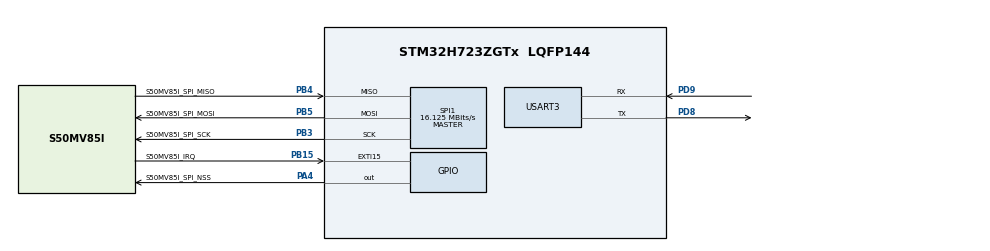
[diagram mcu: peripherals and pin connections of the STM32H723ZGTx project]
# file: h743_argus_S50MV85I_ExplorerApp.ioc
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CORTEX_M7.default_mode_Activation=1
Dma.Request0=SPI1_RX
Dma.Request1=SPI1_TX
Dma.Request2=USART3_RX
Dma.Request3=USART3_TX
Dma.SPI1_RX.0.Direction=DMA_PERIPH_TO_MEMORY
Dma.SPI1_RX.0.EventEnable=DISABLE
Dma.SPI1_RX.0.FIFOMode=DMA_FIFOMODE_DISABLE
Dma.SPI1_RX.0.Instance=DMA1_Stream0
Dma.SPI1_RX.0.MemDataAlignment=DMA_MDATAALIGN_BYTE
Dma.SPI1_RX.0.MemInc=DMA_MINC_ENABLE
Dma.SPI1_RX.0.Mode=DMA_NORMAL
Dma.SPI1_RX.0.PeriphDataAlignment=DMA_PDATAALIGN_BYTE
Dma.SPI1_RX.0.PeriphInc=DMA_PINC_DISABLE
Dma.SPI1_RX.0.Polarity=HAL_DMAMUX_REQ_GEN_RISING
Dma.SPI1_RX.0.Priority=DMA_PRIORITY_LOW
Dma.SPI1_RX.0.RequestNumber=1
Dma.SPI1_RX.0.SignalID=NONE
Dma.SPI1_RX.0.SyncEnable=DISABLE
Dma.SPI1_RX.0.SyncPolarity=HAL_DMAMUX_SYNC_NO_EVENT
Dma.SPI1_RX.0.SyncRequestNumber=1
Dma.SPI1_RX.0.SyncSignalID=NONE
Dma.SPI1_TX.1.Direction=DMA_MEMORY_TO_PERIPH
Dma.SPI1_TX.1.EventEnable=DISABLE
Dma.SPI1_TX.1.FIFOMode=DMA_FIFOMODE_DISABLE
Dma.SPI1_TX.1.Instance=DMA1_Stream1
Dma.SPI1_TX.1.MemDataAlignment=DMA_MDATAALIGN_BYTE
Dma.SPI1_TX.1.MemInc=DMA_MINC_ENABLE
Dma.SPI1_TX.1.Mode=DMA_NORMAL
Dma.SPI1_TX.1.PeriphDataAlignment=DMA_PDATAALIGN_BYTE
Dma.SPI1_TX.1.PeriphInc=DMA_PINC_DISABLE
Dma.SPI1_TX.1.Polarity=HAL_DMAMUX_REQ_GEN_RISING
Dma.SPI1_TX.1.Priority=DMA_PRIORITY_LOW
Dma.SPI1_TX.1.RequestNumber=1
Dma.SPI1_TX.1.SignalID=NONE
Dma.SPI1_TX.1.SyncEnable=DISABLE
Dma.SPI1_TX.1.SyncPolarity=HAL_DMAMUX_SYNC_NO_EVENT
Dma.SPI1_TX.1.SyncRequestNumber=1
Dma.SPI1_TX.1.SyncSignalID=NONE
Dma.USART3_RX.2.Direction=DMA_PERIPH_TO_MEMORY
Dma.USART3_RX.2.EventEnable=DISABLE
Dma.USART3_RX.2.FIFOMode=DMA_FIFOMODE_DISABLE
Dma.USART3_RX.2.Instance=DMA1_Stream2
Dma.USART3_RX.2.MemDataAlignment=DMA_MDATAALIGN_BYTE
Dma.USART3_RX.2.MemInc=DMA_MINC_ENABLE
Dma.USART3_RX.2.Mode=DMA_NORMAL
Dma.USART3_RX.2.PeriphDataAlignment=DMA_PDATAALIGN_BYTE
Dma.USART3_RX.2.PeriphInc=DMA_PINC_DISABLE
Dma.USART3_RX.2.Polarity=HAL_DMAMUX_REQ_GEN_RISING
Dma.USART3_RX.2.Priority=DMA_PRIORITY_LOW
Dma.USART3_RX.2.RequestNumber=1
Dma.USART3_RX.2.SignalID=NONE
Dma.USART3_RX.2.SyncEnable=DISABLE
Dma.USART3_RX.2.SyncPolarity=HAL_DMAMUX_SYNC_NO_EVENT
Dma.USART3_RX.2.SyncRequestNumber=1
Dma.USART3_RX.2.SyncSignalID=NONE
Dma.USART3_TX.3.Direction=DMA_MEMORY_TO_PERIPH
Dma.USART3_TX.3.EventEnable=DISABLE
Dma.USART3_TX.3.FIFOMode=DMA_FIFOMODE_DISABLE
Dma.USART3_TX.3.Instance=DMA1_Stream3
Dma.USART3_TX.3.MemDataAlignment=DMA_MDATAALIGN_BYTE
Dma.USART3_TX.3.MemInc=DMA_MINC_ENABLE
Dma.USART3_TX.3.Mode=DMA_NORMAL
Dma.USART3_TX.3.PeriphDataAlignment=DMA_PDATAALIGN_BYTE
Dma.USART3_TX.3.PeriphInc=DMA_PINC_DISABLE
Dma.USART3_TX.3.Polarity=HAL_DMAMUX_REQ_GEN_RISING
Dma.USART3_TX.3.Priority=DMA_PRIORITY_LOW
Dma.USART3_TX.3.RequestNumber=1
Dma.USART3_TX.3.SignalID=NONE
Dma.USART3_TX.3.SyncEnable=DISABLE
Dma.USART3_TX.3.SyncPolarity=HAL_DMAMUX_SYNC_NO_EVENT
Dma.USART3_TX.3.SyncRequestNumber=1
Dma.USART3_TX.3.SyncSignalID=NONE
Mcu.Family=STM32H7
Mcu.Name=STM32H723ZGTx
Mcu.Package=LQFP144
Mcu.UserConstants=TIM5_BUS_CLK,(HAL_RCC_GetPCLK1Freq() << 1);TIM6_BUS_CLK,(HAL_RCC_GetPCLK1Freq() << 1)
NVIC.DMA1_Stream0_IRQn=true\:0\:0\:false\:false\:true\:false\:true\:true
NVIC.DMA1_Stream1_IRQn=true\:0\:0\:false\:false\:true\:false\:true\:true
NVIC.DMA1_Stream2_IRQn=true\:0\:0\:false\:false\:true\:false\:true\:true
NVIC.DMA1_Stream3_IRQn=true\:0\:0\:false\:false\:true\:false\:true\:true
NVIC.EXTI15_10_IRQn=true\:2\:0\:true\:false\:true\:true\:true\:true
NVIC.PriorityGroup=NVIC_PRIORITYGROUP_4
NVIC.SPI1_IRQn=true\:1\:0\:true\:false\:true\:false\:true\:true
NVIC.TIM6_DAC_IRQn=true\:3\:0\:true\:false\:true\:true\:true\:true
NVIC.USART3_IRQn=true\:0\:0\:false\:false\:true\:true\:true\:true
PA4.GPIO_Label=S50MV85I_SPI_NSS
PA4.GPIO_Speed=GPIO_SPEED_FREQ_VERY_HIGH
PA4.PinState=GPIO_PIN_SET
PA4.Signal=GPIO_Output
PB15.GPIO_Label=S50MV85I_IRQ
PB15.GPIO_ModeDefaultEXTI=GPIO_MODE_IT_FALLING
PB15.GPIO_PuPd=GPIO_PULLUP
PB15.Signal=GPXTI15
PB3(JTDO/TRACESWO).GPIO_Label=S50MV85I_SPI_SCK
PB3(JTDO/TRACESWO).Mode=Full_Duplex_Master
PB3(JTDO/TRACESWO).Signal=SPI1_SCK
PB4(NJTRST).GPIO_Label=S50MV85I_SPI_MISO
PB4(NJTRST).Mode=Full_Duplex_Master
PB4(NJTRST).Signal=SPI1_MISO
PB5.GPIO_Label=S50MV85I_SPI_MOSI
PB5.Mode=Full_Duplex_Master
PB5.Signal=SPI1_MOSI
PD8.Mode=Asynchronous
PD8.Signal=USART3_TX
PD9.Mode=Asynchronous
PD9.Signal=USART3_RX
ProjectManager.HeapSize=0x2000
ProjectManager.StackSize=0x5000
ProjectManager.TargetToolchain=STM32CubeIDE
RCC.ADCFreq_Value=129000000
RCC.APB1Freq_Value=137500000
RCC.APB2Freq_Value=137500000
RCC.APB3Freq_Value=137500000
RCC.APB4Freq_Value=137500000
RCC.CortexFreq_Value=550000000
RCC.D1PPRE=RCC_APB3_DIV2
RCC.D2PPRE1=RCC_APB1_DIV2
RCC.D2PPRE2=RCC_APB2_DIV2
RCC.D3PPRE=RCC_APB4_DIV2
RCC.DIVM1=4
RCC.DIVN1=34
RCC.DIVP1=1
RCC.HCLKFreq_Value=275000000
RCC.HPRE=RCC_HCLK_DIV2
RCC.PLLFRACN=3072
RCC.SPI123CLockSelection=RCC_SPI123CLKSOURCE_PLL2
RCC.SYSCLKFreq_VALUE=550000000
RCC.SYSCLKSource=RCC_SYSCLKSOURCE_PLLCLK
RCC.USBFreq_Value=275000000
SPI1.BaudRatePrescaler=SPI_BAUDRATEPRESCALER_8
SPI1.CLKPhase=SPI_PHASE_2EDGE
SPI1.CLKPolarity=SPI_POLARITY_HIGH
SPI1.CalculateBaudRate=16.125 MBits/s
SPI1.DataSize=SPI_DATASIZE_8BIT
SPI1.Direction=SPI_DIRECTION_2LINES
SPI1.MasterKeepIOState=SPI_MASTER_KEEP_IO_STATE_ENABLE
SPI1.Mode=SPI_MODE_MASTER
SPI1.VirtualType=VM_MASTER
TIM5.Prescaler=(TIM5_BUS_CLK / 1000000) - 1
TIM5.TIM_MasterOutputTrigger=TIM_TRGO_UPDATE
TIM6.Prescaler=(TIM6_BUS_CLK / 1000000) - 1
TIM6.TIM_MasterOutputTrigger=TIM_TRGO_ENABLE
USART3.DMADisableonRxErrorParam=ADVFEATURE_DMA_DISABLEONRXERROR
USART3.OverrunDisableParam=ADVFEATURE_OVERRUN_DISABLE
USART3.VirtualMode-Asynchronous=VM_ASYNC
VP_TIM5_VS_ClockSourceINT.Mode=Internal
VP_TIM6_VS_ClockSourceINT.Mode=Enable_Timer
board=custom

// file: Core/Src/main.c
/* USER CODE BEGIN Header */
/**
  ******************************************************************************
  * @file           : main.c
  * @brief          : Main program body
  ******************************************************************************
  * @attention
  *
  * Copyright (c) 2024 STMicroelectronics.
  * All rights reserved.
  *
  * This software is licensed under terms that can be found in the LICENSE file
  * in the root directory of this software component.
  * If no LICENSE file comes with this software, it is provided AS-IS.
  *
  ******************************************************************************
  */
/* USER CODE END Header */
#include "main.h"
#include "dma.h"
#include "spi.h"
#include "tim.h"
#include "usart.h"
#include "gpio.h"

/* USER CODE BEGIN Includes */
#include <stdio.h>
#include "app_core.h"

/* USER CODE END Includes */

void SystemClock_Config(void);
static void MPU_Config(void);

int main(void)
{

  /* MPU Configuration--------------------------------------------------------*/
  MPU_Config();

  /* MCU Configuration--------------------------------------------------------*/

  /* Reset of all peripherals, Initializes the Flash interface and the Systick. */
  HAL_Init();

  /* Configure the system clock */
  SystemClock_Config();

  /* Initialize all configured peripherals */
  MX_GPIO_Init();
  MX_DMA_Init();
  MX_SPI1_Init();
  MX_TIM5_Init();
  MX_TIM6_Init();
  MX_USART3_UART_Init();

  /* Infinite loop */
  /* USER CODE BEGIN WHILE */
  app_main();

  while (1)
  {
	  printf("STM32 PANIC!!!!!!\n\t");
	  HAL_Delay(100);
    /* USER CODE END WHILE */

  }
}

void SystemClock_Config(void)
{
  RCC_OscInitTypeDef RCC_OscInitStruct = {0};
  RCC_ClkInitTypeDef RCC_ClkInitStruct = {0};

  /** Supply configuration update enable
  */
  HAL_PWREx_ConfigSupply(PWR_LDO_SUPPLY);

  /** Configure the main internal regulator output voltage
  */
  __HAL_PWR_VOLTAGESCALING_CONFIG(PWR_REGULATOR_VOLTAGE_SCALE0);

  while(!__HAL_PWR_GET_FLAG(PWR_FLAG_VOSRDY)) {}

  /** Initializes the RCC Oscillators according to the specified parameters
  * in the RCC_OscInitTypeDef structure.
  */
  RCC_OscInitStruct.OscillatorType = RCC_OSCILLATORTYPE_HSI;
  RCC_OscInitStruct.HSIState = RCC_HSI_DIV1;
  RCC_OscInitStruct.HSICalibrationValue = 64;
  RCC_OscInitStruct.PLL.PLLState = RCC_PLL_ON;
  RCC_OscInitStruct.PLL.PLLSource = RCC_PLLSOURCE_HSI;
  RCC_OscInitStruct.PLL.PLLM = 4;
  RCC_OscInitStruct.PLL.PLLN = 34;
  RCC_OscInitStruct.PLL.PLLP = 1;
  RCC_OscInitStruct.PLL.PLLQ = 2;
  RCC_OscInitStruct.PLL.PLLR = 2;
  RCC_OscInitStruct.PLL.PLLRGE = RCC_PLL1VCIRANGE_3;
  RCC_OscInitStruct.PLL.PLLVCOSEL = RCC_PLL1VCOWIDE;
  RCC_OscInitStruct.PLL.PLLFRACN = 3072;
  if (HAL_RCC_OscConfig(&RCC_OscInitStruct) != HAL_OK)
  {
    Error_Handler();
  }

  /** Initializes the CPU, AHB and APB buses clocks
  */
  RCC_ClkInitStruct.ClockType = RCC_CLOCKTYPE_HCLK|RCC_CLOCKTYPE_SYSCLK
                              |RCC_CLOCKTYPE_PCLK1|RCC_CLOCKTYPE_PCLK2
                              |RCC_CLOCKTYPE_D3PCLK1|RCC_CLOCKTYPE_D1PCLK1;
  RCC_ClkInitStruct.SYSCLKSource = RCC_SYSCLKSOURCE_PLLCLK;
  RCC_ClkInitStruct.SYSCLKDivider = RCC_SYSCLK_DIV1;
  RCC_ClkInitStruct.AHBCLKDivider = RCC_HCLK_DIV2;
  RCC_ClkInitStruct.APB3CLKDivider = RCC_APB3_DIV2;
  RCC_ClkInitStruct.APB1CLKDivider = RCC_APB1_DIV2;
  RCC_ClkInitStruct.APB2CLKDivider = RCC_APB2_DIV2;
  RCC_ClkInitStruct.APB4CLKDivider = RCC_APB4_DIV2;

  if (HAL_RCC_ClockConfig(&RCC_ClkInitStruct, FLASH_LATENCY_3) != HAL_OK)
  {
    Error_Handler();
  }
}

 /* MPU Configuration */

void MPU_Config(void)
{
  MPU_Region_InitTypeDef MPU_InitStruct = {0};

  /* Disables the MPU */
  HAL_MPU_Disable();

  /** Initializes and configures the Region and the memory to be protected
  */
  MPU_InitStruct.Enable = MPU_REGION_ENABLE;
  MPU_InitStruct.Number = MPU_REGION_NUMBER0;
  MPU_InitStruct.BaseAddress = 0x0;
  MPU_InitStruct.Size = MPU_REGION_SIZE_4GB;
  MPU_InitStruct.SubRegionDisable = 0x87;
  MPU_InitStruct.TypeExtField = MPU_TEX_LEVEL0;
  MPU_InitStruct.AccessPermission = MPU_REGION_NO_ACCESS;
  MPU_InitStruct.DisableExec = MPU_INSTRUCTION_ACCESS_DISABLE;
  MPU_InitStruct.IsShareable = MPU_ACCESS_SHAREABLE;
  MPU_InitStruct.IsCacheable = MPU_ACCESS_NOT_CACHEABLE;
  MPU_InitStruct.IsBufferable = MPU_ACCESS_NOT_BUFFERABLE;

  HAL_MPU_ConfigRegion(&MPU_InitStruct);
  /* Enables the MPU */
  HAL_MPU_Enable(MPU_PRIVILEGED_DEFAULT);

}

void Error_Handler(void)
{
  __disable_irq();
  while (1)
  {
  }
}
